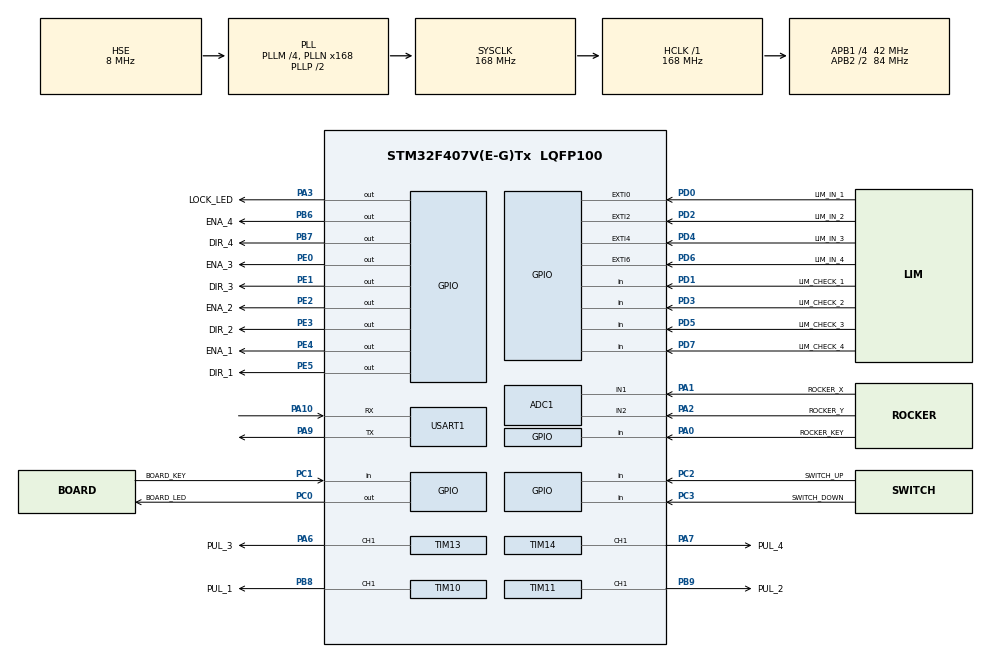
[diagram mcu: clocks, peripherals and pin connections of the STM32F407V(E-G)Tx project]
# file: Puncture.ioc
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ADC1.Channel-0\#ChannelRegularConversion=ADC_CHANNEL_1
ADC1.Channel-1\#ChannelRegularConversion=ADC_CHANNEL_2
ADC1.ContinuousConvMode=ENABLE
ADC1.DMAContinuousRequests=ENABLE
ADC1.EOCSelection=ADC_EOC_SEQ_CONV
ADC1.NbrOfConversion=2
ADC1.NbrOfConversionFlag=1
ADC1.Rank-0\#ChannelRegularConversion=1
ADC1.Rank-1\#ChannelRegularConversion=2
ADC1.SamplingTime-0\#ChannelRegularConversion=ADC_SAMPLETIME_15CYCLES
ADC1.SamplingTime-1\#ChannelRegularConversion=ADC_SAMPLETIME_15CYCLES
ADC1.master=1
Dma.ADC1.1.Direction=DMA_PERIPH_TO_MEMORY
Dma.ADC1.1.FIFOMode=DMA_FIFOMODE_DISABLE
Dma.ADC1.1.Instance=DMA2_Stream0
Dma.ADC1.1.MemDataAlignment=DMA_MDATAALIGN_WORD
Dma.ADC1.1.MemInc=DMA_MINC_ENABLE
Dma.ADC1.1.Mode=DMA_CIRCULAR
Dma.ADC1.1.PeriphDataAlignment=DMA_PDATAALIGN_WORD
Dma.ADC1.1.PeriphInc=DMA_PINC_DISABLE
Dma.ADC1.1.Priority=DMA_PRIORITY_MEDIUM
Dma.Request0=USART1_TX
Dma.Request1=ADC1
Dma.USART1_TX.0.Direction=DMA_MEMORY_TO_PERIPH
Dma.USART1_TX.0.FIFOMode=DMA_FIFOMODE_DISABLE
Dma.USART1_TX.0.Instance=DMA2_Stream7
Dma.USART1_TX.0.MemDataAlignment=DMA_MDATAALIGN_BYTE
Dma.USART1_TX.0.MemInc=DMA_MINC_ENABLE
Dma.USART1_TX.0.Mode=DMA_NORMAL
Dma.USART1_TX.0.PeriphDataAlignment=DMA_PDATAALIGN_BYTE
Dma.USART1_TX.0.PeriphInc=DMA_PINC_DISABLE
Dma.USART1_TX.0.Priority=DMA_PRIORITY_LOW
Mcu.Family=STM32F4
Mcu.Name=STM32F407V(E-G)Tx
Mcu.Package=LQFP100
NVIC.DMA2_Stream7_IRQn=true\:3\:3\:true\:false\:true\:false\:true\:true
NVIC.EXTI0_IRQn=true\:1\:0\:true\:false\:true\:true\:true\:true
NVIC.EXTI2_IRQn=true\:1\:1\:true\:false\:true\:true\:true\:true
NVIC.EXTI4_IRQn=true\:1\:2\:true\:false\:true\:true\:true\:true
NVIC.EXTI9_5_IRQn=true\:1\:3\:true\:false\:true\:true\:true\:true
NVIC.PriorityGroup=NVIC_PRIORITYGROUP_2
NVIC.TIM1_TRG_COM_TIM11_IRQn=true\:2\:1\:true\:false\:true\:true\:true\:true
NVIC.TIM1_UP_TIM10_IRQn=true\:2\:0\:true\:false\:true\:true\:true\:true
NVIC.TIM3_IRQn=true\:3\:2\:true\:false\:true\:true\:true\:true
NVIC.TIM8_TRG_COM_TIM14_IRQn=true\:2\:3\:true\:false\:true\:true\:true\:true
NVIC.TIM8_UP_TIM13_IRQn=true\:2\:2\:true\:false\:true\:true\:true\:true
NVIC.USART1_IRQn=true\:3\:0\:true\:false\:true\:true\:true\:true
PA0-WKUP.GPIO_Label=ROCKER_KEY
PA0-WKUP.GPIO_PuPd=GPIO_PULLDOWN
PA0-WKUP.Signal=GPIO_Input
PA1.GPIO_Label=ROCKER_X
PA1.Signal=ADCx_IN1
PA10.Mode=Asynchronous
PA10.Signal=USART1_RX
PA13.Mode=Serial_Wire
PA13.Signal=SYS_JTMS-SWDIO
PA14.Mode=Serial_Wire
PA14.Signal=SYS_JTCK-SWCLK
PA2.GPIO_Label=ROCKER_Y
PA2.Signal=ADCx_IN2
PA3.GPIO_Label=LOCK_LED
PA3.GPIO_PuPd=GPIO_PULLUP
PA3.PinState=GPIO_PIN_SET
PA3.Signal=GPIO_Output
PA6.GPIO_Label=PUL_3
PA6.Signal=S_TIM13_CH1
PA7.GPIO_Label=PUL_4
PA7.Signal=S_TIM14_CH1
PA9.Mode=Asynchronous
PA9.Signal=USART1_TX
PB6.GPIO_Label=ENA_4
PB6.GPIO_PuPd=GPIO_PULLDOWN
PB6.Signal=GPIO_Output
PB7.GPIO_Label=DIR_4
PB7.GPIO_PuPd=GPIO_PULLDOWN
PB7.GPIO_Speed=GPIO_SPEED_FREQ_HIGH
PB7.Signal=GPIO_Output
PB8.GPIO_Label=PUL_1
PB8.Signal=S_TIM10_CH1
PB9.GPIO_Label=PUL_2
PB9.Signal=S_TIM11_CH1
PC0.GPIO_Label=BOARD_LED
PC0.GPIO_PuPd=GPIO_PULLUP
PC0.GPIO_Speed=GPIO_SPEED_FREQ_LOW
PC0.PinState=GPIO_PIN_SET
PC0.Signal=GPIO_Output
PC1.GPIO_Label=BOARD_KEY
PC1.GPIO_PuPd=GPIO_PULLUP
PC1.Signal=GPIO_Input
PC14-OSC32_IN.Mode=LSE-External-Oscillator
PC14-OSC32_IN.Signal=RCC_OSC32_IN
PC15-OSC32_OUT.Mode=LSE-External-Oscillator
PC15-OSC32_OUT.Signal=RCC_OSC32_OUT
PC2.GPIO_Label=SWITCH_UP
PC2.GPIO_PuPd=GPIO_PULLUP
PC2.Signal=GPIO_Input
PC3.GPIO_Label=SWITCH_DOWN
PC3.GPIO_Mode=GPIO_MODE_INPUT
PC3.GPIO_PuPd=GPIO_PULLUP
PC3.Signal=GPIO_Input
PD0.GPIO_Label=LIM_IN_1
PD0.GPIO_PuPd=GPIO_PULLDOWN
PD0.Signal=GPXTI0
PD1.GPIO_Label=LIM_CHECK_1
PD1.GPIO_PuPd=GPIO_PULLDOWN
PD1.Signal=GPIO_Input
PD2.GPIO_Label=LIM_IN_2
PD2.GPIO_PuPd=GPIO_PULLDOWN
PD2.Signal=GPXTI2
PD3.GPIO_Label=LIM_CHECK_2
PD3.GPIO_PuPd=GPIO_PULLDOWN
PD3.Signal=GPIO_Input
PD4.GPIO_Label=LIM_IN_3
PD4.GPIO_PuPd=GPIO_PULLDOWN
PD4.Signal=GPXTI4
PD5.GPIO_Label=LIM_CHECK_3
PD5.GPIO_PuPd=GPIO_PULLDOWN
PD5.Signal=GPIO_Input
PD6.GPIO_Label=LIM_IN_4
PD6.GPIO_PuPd=GPIO_PULLDOWN
PD6.Signal=GPXTI6
PD7.GPIO_Label=LIM_CHECK_4
PD7.GPIO_PuPd=GPIO_PULLDOWN
PD7.Signal=GPIO_Input
PE0.GPIO_Label=ENA_3
PE0.GPIO_PuPd=GPIO_PULLDOWN
PE0.Signal=GPIO_Output
PE1.GPIO_Label=DIR_3
PE1.GPIO_PuPd=GPIO_PULLDOWN
PE1.GPIO_Speed=GPIO_SPEED_FREQ_HIGH
PE1.Signal=GPIO_Output
PE2.GPIO_Label=ENA_2
PE2.GPIO_PuPd=GPIO_PULLDOWN
PE2.Signal=GPIO_Output
PE3.GPIO_Label=DIR_2
PE3.GPIO_PuPd=GPIO_PULLDOWN
PE3.GPIO_Speed=GPIO_SPEED_FREQ_HIGH
PE3.Signal=GPIO_Output
PE4.GPIO_Label=ENA_1
PE4.GPIO_PuPd=GPIO_PULLDOWN
PE4.Signal=GPIO_Output
PE5.GPIO_Label=DIR_1
PE5.GPIO_PuPd=GPIO_PULLDOWN
PE5.GPIO_Speed=GPIO_SPEED_FREQ_HIGH
PE5.Signal=GPIO_Output
PH0-OSC_IN.Mode=HSE-External-Oscillator
PH0-OSC_IN.Signal=RCC_OSC_IN
PH1-OSC_OUT.Mode=HSE-External-Oscillator
PH1-OSC_OUT.Signal=RCC_OSC_OUT
ProjectManager.HeapSize=0x200
ProjectManager.StackSize=0x400
ProjectManager.TargetToolchain=MDK-ARM V5
RCC.48MHZClocksFreq_Value=84000000
RCC.AHBFreq_Value=168000000
RCC.APB1CLKDivider=RCC_HCLK_DIV4
RCC.APB1Freq_Value=42000000
RCC.APB1TimFreq_Value=84000000
RCC.APB2CLKDivider=RCC_HCLK_DIV2
RCC.APB2Freq_Value=84000000
RCC.APB2TimFreq_Value=168000000
RCC.CortexFreq_Value=168000000
RCC.HCLKFreq_Value=168000000
RCC.HSE_VALUE=8000000
RCC.HSI_VALUE=16000000
RCC.PLLM=4
RCC.PLLN=168
RCC.PLLSourceVirtual=RCC_PLLSOURCE_HSE
RCC.SYSCLKFreq_VALUE=168000000
RCC.SYSCLKSource=RCC_SYSCLKSOURCE_PLLCLK
RCC.VCOOutputFreq_Value=336000000
SH.ADCx_IN1.0=ADC1_IN1,IN1
SH.ADCx_IN2.0=ADC1_IN2,IN2
SH.S_TIM10_CH1.0=TIM10_CH1,PWM Generation1 CH1
SH.S_TIM11_CH1.0=TIM11_CH1,PWM Generation1 CH1
SH.S_TIM13_CH1.0=TIM13_CH1,PWM Generation1 CH1
SH.S_TIM14_CH1.0=TIM14_CH1,PWM Generation1 CH1
TIM10.Channel=TIM_CHANNEL_1
TIM10.Period=100-1
TIM10.Prescaler=168-1
TIM11.Channel=TIM_CHANNEL_1
TIM11.Period=100-1
TIM11.Prescaler=168-1
TIM13.Channel=TIM_CHANNEL_1
TIM13.Period=100-1
TIM13.Prescaler=84-1
TIM14.Channel=TIM_CHANNEL_1
TIM14.Period=100-1
TIM14.Prescaler=84-1
TIM3.Period=10000-1
TIM3.Prescaler=84-1
USART1.VirtualMode=VM_ASYNC
VP_TIM10_VS_ClockSourceINT.Mode=Enable_Timer
VP_TIM11_VS_ClockSourceINT.Mode=Enable_Timer
VP_TIM13_VS_ClockSourceINT.Mode=Enable_Timer
VP_TIM14_VS_ClockSourceINT.Mode=Enable_Timer
VP_TIM3_VS_ClockSourceINT.Mode=Internal
board=custom

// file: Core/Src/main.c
/* USER CODE BEGIN Header */
/**
  ******************************************************************************
  * @file           : main.c
  * @brief          : Main program body
  ******************************************************************************
  * @attention
  *
  * Copyright (c) 2022 STMicroelectronics.
  * All rights reserved.
  *
  * This software is licensed under terms that can be found in the LICENSE file
  * in the root directory of this software component.
  * If no LICENSE file comes with this software, it is provided AS-IS.
  *
  ******************************************************************************
  */
/* USER CODE END Header */
#include "main.h"
#include "adc.h"
#include "dma.h"
#include "tim.h"
#include "usart.h"
#include "gpio.h"

/* USER CODE BEGIN Includes */
#include "demo.h"
/* USER CODE END Includes */

void SystemClock_Config(void);

int main(void)
{

  /* MCU Configuration--------------------------------------------------------*/

  /* Reset of all peripherals, Initializes the Flash interface and the Systick. */
  HAL_Init();

  /* Configure the system clock */
  SystemClock_Config();

  /* Initialize all configured peripherals */
  MX_GPIO_Init();
  MX_DMA_Init();
  MX_TIM10_Init();
  MX_TIM11_Init();
  MX_TIM13_Init();
  MX_TIM14_Init();
  MX_USART1_UART_Init();
  MX_ADC1_Init();
  MX_TIM3_Init();

  /* Infinite loop */
  /* USER CODE BEGIN WHILE */
  while (1)
  {
    System_Running();
    /* USER CODE END WHILE */

  }
}

void SystemClock_Config(void)
{
  RCC_OscInitTypeDef RCC_OscInitStruct = {0};
  RCC_ClkInitTypeDef RCC_ClkInitStruct = {0};

  /** Configure the main internal regulator output voltage
  */
  __HAL_RCC_PWR_CLK_ENABLE();
  __HAL_PWR_VOLTAGESCALING_CONFIG(PWR_REGULATOR_VOLTAGE_SCALE1);

  /** Initializes the RCC Oscillators according to the specified parameters
  * in the RCC_OscInitTypeDef structure.
  */
  RCC_OscInitStruct.OscillatorType = RCC_OSCILLATORTYPE_HSE;
  RCC_OscInitStruct.HSEState = RCC_HSE_ON;
  RCC_OscInitStruct.PLL.PLLState = RCC_PLL_ON;
  RCC_OscInitStruct.PLL.PLLSource = RCC_PLLSOURCE_HSE;
  RCC_OscInitStruct.PLL.PLLM = 4;
  RCC_OscInitStruct.PLL.PLLN = 168;
  RCC_OscInitStruct.PLL.PLLP = RCC_PLLP_DIV2;
  RCC_OscInitStruct.PLL.PLLQ = 4;
  if (HAL_RCC_OscConfig(&RCC_OscInitStruct) != HAL_OK)
  {
    Error_Handler();
  }

  /** Initializes the CPU, AHB and APB buses clocks
  */
  RCC_ClkInitStruct.ClockType = RCC_CLOCKTYPE_HCLK|RCC_CLOCKTYPE_SYSCLK
                              |RCC_CLOCKTYPE_PCLK1|RCC_CLOCKTYPE_PCLK2;
  RCC_ClkInitStruct.SYSCLKSource = RCC_SYSCLKSOURCE_PLLCLK;
  RCC_ClkInitStruct.AHBCLKDivider = RCC_SYSCLK_DIV1;
  RCC_ClkInitStruct.APB1CLKDivider = RCC_HCLK_DIV4;
  RCC_ClkInitStruct.APB2CLKDivider = RCC_HCLK_DIV2;

  if (HAL_RCC_ClockConfig(&RCC_ClkInitStruct, FLASH_LATENCY_5) != HAL_OK)
  {
    Error_Handler();
  }
}

void Error_Handler(void)
{
  __disable_irq();
  while (1)
  {
  }
}
